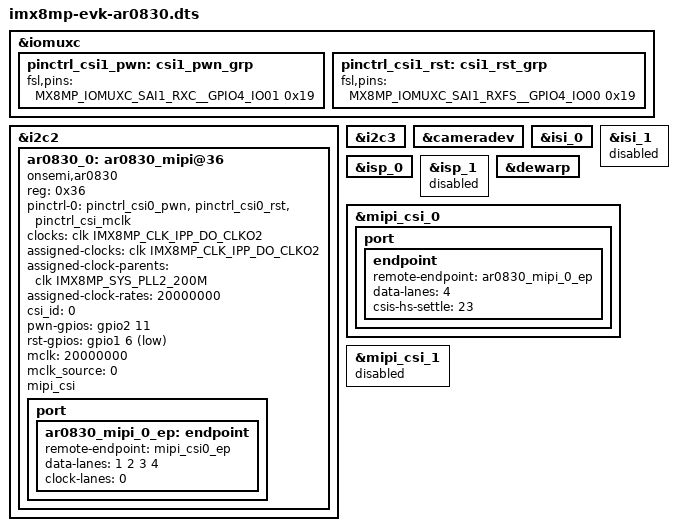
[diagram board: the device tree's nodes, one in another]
/*
 * Copyright 2021, 2024-2025 NXP
 * Copyright 2022 Semiconductor Components Industries, LLC ("onsemi").
 *
 * SPDX-License-Identifier: (GPL-2.0-only OR MIT)
 */

/dts-v1/;

#include "imx8mp-evk.dts"

&iomuxc {
	pinctrl_csi1_pwn: csi1_pwn_grp {
		fsl,pins = <
			MX8MP_IOMUXC_SAI1_RXC__GPIO4_IO01	0x19
		>;
	};

	pinctrl_csi1_rst: csi1_rst_grp {
		fsl,pins = <
			MX8MP_IOMUXC_SAI1_RXFS__GPIO4_IO00	0x19
		>;
	};
};

&i2c2 {
	/delete-node/ov5640_mipi@3c;

	ar0830_0: ar0830_mipi@36 {
		compatible = "onsemi,ar0830";
		reg = <0x36>;
		pinctrl-names = "default";
		pinctrl-0 = <&pinctrl_csi0_pwn>, <&pinctrl_csi0_rst>, <&pinctrl_csi_mclk>;
		clocks = <&clk IMX8MP_CLK_IPP_DO_CLKO2>;
		clock-names = "csi_mclk";
		assigned-clocks = <&clk IMX8MP_CLK_IPP_DO_CLKO2>;
		assigned-clock-parents = <&clk IMX8MP_SYS_PLL2_200M>;
		assigned-clock-rates = <20000000>;
		csi_id = <0>;
		pwn-gpios = <&gpio2 11 GPIO_ACTIVE_HIGH>;
		rst-gpios = <&gpio1 6 GPIO_ACTIVE_LOW>;
		mclk = <20000000>;
		mclk_source = <0>;
		mipi_csi;
		status = "okay";

		port {
			ar0830_mipi_0_ep: endpoint {
				remote-endpoint = <&mipi_csi0_ep>;
				data-lanes = <1 2 3 4>;
				clock-lanes = <0>;
			};
		};
	};
};

&i2c3 {
	/delete-node/ov5640_mipi@3c;

};

&cameradev {
	status = "okay";
};

&isi_0 {
	status = "okay";
};

&isi_1 {
	status = "disabled";
};

&isp_0 {
	status = "okay";
};

&isp_1 {
	status = "disabled";
};

&dewarp {
	status = "okay";
};

&mipi_csi_0 {
	status = "okay";
	//clock-frequency = <266000000>;
	//assigned-clock-parents = <&clk IMX8MP_SYS_PLL1_266M>;
	//assigned-clock-rates = <266000000>;

	port {
		endpoint {
			remote-endpoint = <&ar0830_mipi_0_ep>;
			data-lanes = <4>;
			csis-hs-settle = <23>;
		};
	};
};

&mipi_csi_1 {
	status = "disabled";
	/delete-property/ #address-cells;
	/delete-property/ #size-cells;
	/delete-node/port@1;
};
